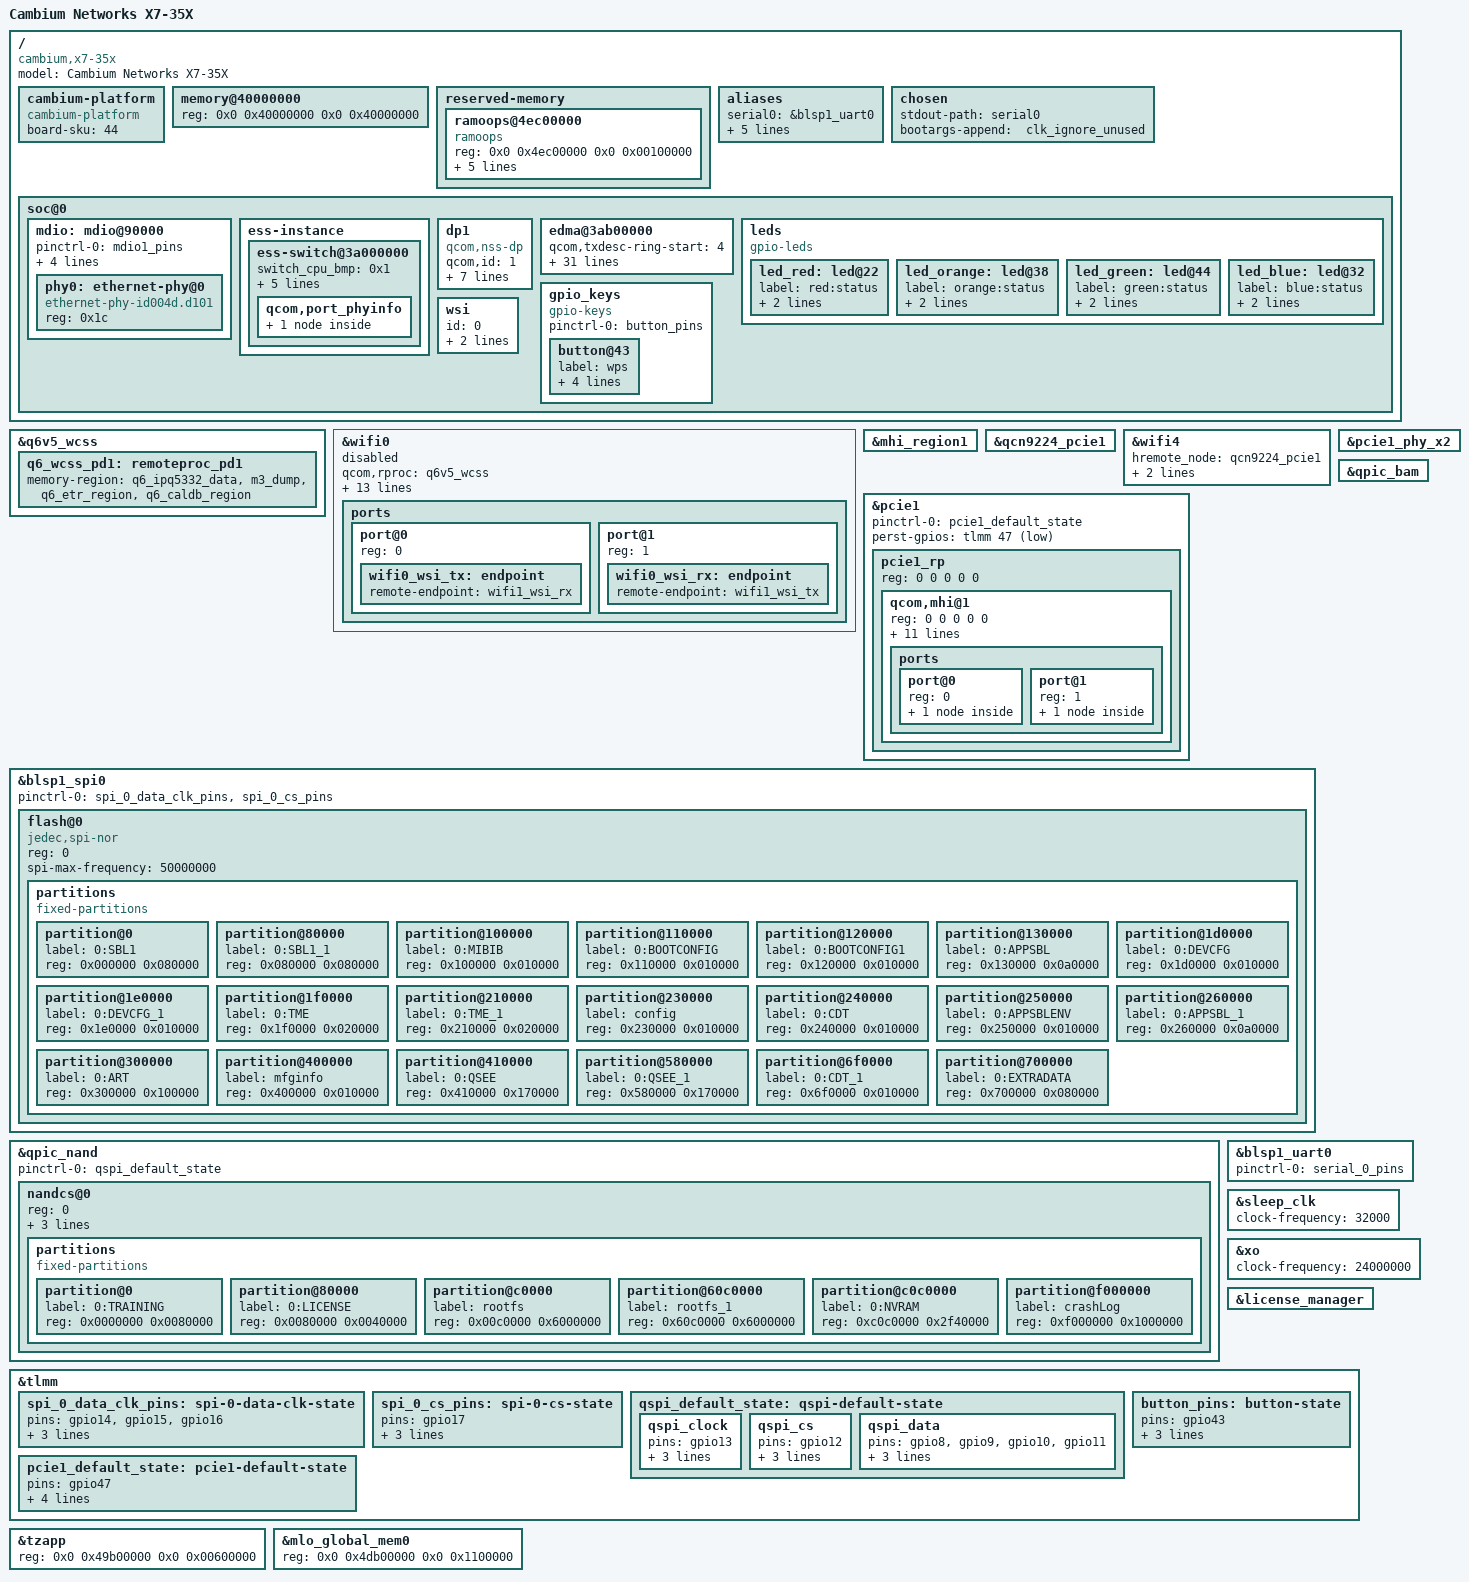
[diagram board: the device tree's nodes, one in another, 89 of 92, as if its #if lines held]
// SPDX-License-Identifier: (GPL-2.0+ OR BSD-3-Clause)
/*
 * Cambium Networks X7-35X device tree source
 *
 * IPQ5332 (2.4 GHz, AHB) + QCN9224 (5 and 6 GHz, PCIe1 x2), tri-band 2x2,
 * one 2.5 GbE port, 1 GiB of DDR, 8 MiB SPI NOR + 256 MiB SPI NAND in two
 * 96 MiB A/B firmware banks. Board codename "acadia", /proc/sku 44,
 * U-Boot hwid=1, machid=0x8060000. Secure boot is off on this unit
 * (qfprom0/authenticate = 0).
 *
 * The OEM tree is "Qualcomm Technologies, Inc. IPQ5332/AP-MI01.6"
 * (qcom,ipq5332-ap-mi01.6), i.e. the same reference design the EAP105 and
 * every other board in this feed descends from, so this file is the EAP105
 * with one port instead of two, the Cambium flash map declared explicitly,
 * and Cambium's LED/button/PHY GPIOs.
 *
 * Every value here comes from one of three places, and nothing else:
 *   - measured on this unit (flash offsets, MAC environment, UBI layout),
 *   - Phil Taylor's validated X7-35X trees (GPIOs, PHY, UNIPHY, LEDs,
 *     reserved memory, board ids),
 *   - the EAP105 twin in this feed (QSDK bindings: nss-dp, ess-switch,
 *     edma, wsi, the QCN9224 MHI node).
 * Anything that could not be sourced from one of those is marked
 * TODO(verify on hardware) rather than guessed.
 */

/dts-v1/;

#define __RPROC_DISABLE_MPD_SUPPORT__

#include <dt-bindings/gpio/gpio.h>
#include <dt-bindings/input/input.h>
#include <dt-bindings/leds/common.h>
#include "ipq5332.dtsi"
#ifdef __IPQ_MEM_PROFILE_512_MB__
#include "ipq5332-512MB-memory.dtsi"
#elif !defined(__IPQ_MEM_PROFILE_256_MB__)
#include "ipq5332-default-memory.dtsi"
#endif

/ {
	model = "Cambium Networks X7-35X";
	compatible = "cambium,x7-35x", "qcom,ipq5332-ap-mi01.6", "qcom,ipq5332";

	/*
	 * The OEM tree has a cambium-platform node whose board-sku is what the
	 * OEM userspace (and Phil's miami-board-data) reads to pick board files
	 * and A/B behaviour. Measured /proc/sku = 44 = 0x2c. Nothing in wlan-ap
	 * reads it today; it is kept so a later Cambium-specific script can use
	 * the same source of truth as the OEM, instead of parsing the model
	 * string.
	 */
	cambium-platform {
		compatible = "cambium-platform";
		board-sku = <44>;
	};


	/*
	 * 2 GiB, MEASURED on this unit -- stock reports MemTotal 1932236 kB and
	 * /proc/device-tree/memory/reg = 0x40000000 size 0x80000000. An earlier
	 * revision of this file said 1 GiB and claimed the Cambium loader was not
	 * known to perform the QSDK memory fixup; the OEM FDT dump disproves both.
	 * That dump carries machid, tz_version, boot_version and a /memreserve/
	 * for the relocated FDT, none of which exist before the loader fixups run.
	 *
	 * Declaring LESS than the installed RAM is merely wasteful; declaring MORE
	 * is fatal. Set to 1 GiB on purpose for now: that is what m0vse's validated
	 * acadia tree declares, and this file is converging on the only known-good
	 * configuration for this SKU. Raise it to 0x80000000 once the board boots.
	 */
	memory@40000000 {
		device_type = "memory";
		reg = <0x0 0x40000000 0x0 0x40000000>;
	};

	/*
	 * ramoops at 0x4ec00000, to get this board to talk without a console.
	 *
	 * An earlier revision of this file deliberately had NO ramoops node,
	 * because the EAP105 twin puts ramoops@49a00000 which lands inside the
	 * tzapp window. That reasoning only ruled out THAT address. 0x4ec00000 is
	 * chosen for one specific property: it is free in our map (once mlo is
	 * corrected below) AND reserved no-map by STOCK, whose OEM DTB has
	 * qcn9224_pcie0@4ec00000 with pcie0 disabled. So stock never writes it,
	 * and after a failed boot self-reverts into stock we can read the buffer
	 * back through stock's /dev/mem. (m0vse's recovery image cannot do this --
	 * it ships no /dev/mem, no pstore and no kexec.)
	 *
	 * mem-type = <1> (uncached) is REQUIRED, not decorative: with a cached
	 * mapping the zone's 12-byte header is still a dirty cache line at reset
	 * while the payload gets written back by capacity eviction, so
	 * persistent_ram_post_init() reads size == 0 and throws the dump away.
	 * That is the WIFI-15350 lesson and it cost a day on the AX820.
	 *
	 * console-size is the whole point: it captures EVERY console line, not
	 * just panics, which is what is needed when the symptom is silence.
	 */
	reserved-memory {
		#address-cells = <2>;
		#size-cells = <2>;
		ranges;

		ramoops@4ec00000 {
			compatible = "ramoops";
			reg = <0x0 0x4ec00000 0x0 0x00100000>;
			record-size  = <0x20000>;
			console-size = <0x80000>;
			pmsg-size    = <0x20000>;
			mem-type     = <1>;
			no-map;
		};
	};

	aliases {
		serial0 = &blsp1_uart0;

		/*
		 * ONE Ethernet port, and it must be ethernet0.
		 *
		 * U-Boot's fdt_fixup_ethernet() walks the aliases ethernet0,
		 * ethernet1, ... and stamps local-mac-address/mac-address onto
		 * each aliased node from the environment variables ethaddr,
		 * eth1addr, ... in that order. Measured on this unit:
		 *   ethaddr = 90:6d:62:b0:64:48 == the label MAC
		 *   eth1addr  does not exist
		 * so the single port must be alias ethernet0 to collect ethaddr.
		 * Aliasing it as ethernet1 (what the XV2-2T0/2T1 and XE3-4 need,
		 * because those carry the label MAC in ethaddr and label+1 in
		 * eth1addr) would leave local-mac-address as the all-zero
		 * placeholder, and nss-dp substitutes a RANDOM MAC for an invalid
		 * one -- a new serial every boot, matching no certificate, so the
		 * controller closes the session right after pushing config.
		 * This is the XV2-2 situation exactly, and the same answer.
		 *
		 * The ipq53xx equivalent of "dp1 aliased as ethernet0" is the
		 * emplus_wap7635 / zyxel_nwa50be single-port pattern already in
		 * this feed: one /soc/dp1 node, aliased ethernet0. The alias
		 * value is a path string, not a phandle, because the dp nodes
		 * carry no label in ipq5332.dtsi -- they are board nodes.
		 */
		ethernet0 = "/soc/dp1";

		led-boot = &led_orange;
		led-failsafe = &led_orange;
		led-running = &led_green;
		led-upgrade = &led_orange;
	};

	chosen {
		stdout-path = "serial0";
		bootargs-append = " clk_ignore_unused";
	};

	soc@0 {
		mdio: mdio@90000 {
			pinctrl-0 = <&mdio1_pins>;	/* gpio27 mdc1, gpio28 mdio1 */
			pinctrl-names = "default";
			/*
			 * QCA8081 reset is GPIO 25 on this board (the EAP105 uses
			 * GPIO 25 for its reset BUTTON -- do not cross-read the two
			 * trees).
			 *
			 * THE POLARITY IS LOAD-BEARING. Do not "correct" it to flag 0
			 * to match the OEM device tree. The OEM 5.4 kernel binds a
			 * driver that hard-codes the pulse and ignores the DT flag, so
			 * its 0 means nothing. On 6.6, qcom,qca-mdio binds
			 * drivers/net/mdio/mdio-ipq4019.c, which takes the line with
			 * devm_gpiod_get_array_optional(..., GPIOD_OUT_LOW) and in
			 * ipq_mdio_reset() asserts, sleeps, then DEASSERTS -- gpiod
			 * honours the flag. With GPIO_ACTIVE_LOW (this value, and
			 * Phil Taylor's validated tree) the pin ends HIGH, releasing
			 * QCA8081 RESET_N. With flag 0 it would end LOW, holding the
			 * PHY in reset: no link, no network, and on a unit with no
			 * serial console, no diagnostics either.
			 *
			 * ipq_mdio_reset() also enables the UNIPHY AHB/SYS clocks and
			 * sets BIT(0) at each eth_ldo before pulsing, which is the
			 * reference-clock enable Phil had to add for mainline -- so
			 * no extra handling is needed here.
			 */
			phy-reset-gpio = <&tlmm 25 GPIO_ACTIVE_LOW>;
			phyaddr_fixup = <0xC90F018>;
			uniphyaddr_fixup = <0xC90F014>;
			mdio_clk_fixup;	/* MDIO clock sequence fix up flag */
			status = "okay";

			/*
			 * QCA8081 (ethernet-phy-id004d.d101) at MDIO address 0x1c.
			 * C22, single port, 1G/2.5G; it presents 2500BASE-X to the
			 * MAC at 2.5 Gbit/s and SGMII below that.
			 *
			 * TODO(verify on hardware): Phil documents that the OEM
			 * qca_mdio_probe enables GCC_UNIPHY0_AHB/SYS and then sets
			 * bit 0 of UNIPHY0 + 0x610 (0x07a00610) -- the QCA8081's
			 * 50 MHz reference clock -- waits 100 ms, and only then
			 * pulses the PHY reset. QSDK does its UNIPHY bring-up in
			 * qca-ssdk from switch_mac_mode rather than from the device
			 * tree, and whether ssdk sets that same bit is NOT
			 * established. If MDIO reads return 0xffff / the PHY never
			 * appears, that bit is the first thing to check, and
			 * base-files/etc/init.d/phy_quirks is the house place to
			 * poke it (see 90-phy_quirks.fragment).
			 */
			phy0: ethernet-phy@0 {
				reg = <0x1c>;
				compatible = "ethernet-phy-id004d.d101";
			};
		};

		ess-instance {
			ess-switch@3a000000 {
				switch_cpu_bmp = <0x1>;		/* cpu port bitmap */
				switch_lan_bmp = <0x2>;		/* lan port bitmap: PPE port 1 */
				switch_wan_bmp = <0x0>;		/* wan port bitmap */
				/*
				 * UNIPHY0 carries the only port. 0xc is
				 * PORT_WRAPPER_SGMII_PLUS (the in-tree comment in
				 * ipq5332-asterfusion-ap7330.dts states 0xc =
				 * SGMII_PLUS and 0xe = 10GBASE_R), which is the 2.5G
				 * mode a QCA8081 needs.
				 *
				 * TODO(verify on hardware): the other single-port
				 * boards in this feed (emplus_wap7635,
				 * zyxel_nwa50be) use 0xf on uniphy0, but both sit
				 * behind a different PHY. If the link never comes up
				 * at 2.5G, or comes up only at 1G, try 0xf before
				 * touching anything else. UNIPHY1 and UNIPHY2 are
				 * unused on this board (0xff = not present).
				 */
				switch_mac_mode = <0xc>;	/* uniphy0 */
				switch_mac_mode1 = <0xff>;	/* uniphy1 unused */
				switch_mac_mode2 = <0xff>;	/* uniphy2 unused */

				qcom,port_phyinfo {
					port@0 {
						port_id = <1>;
						phy_address = <0x1c>;
						mdiobus = <&mdio>;
					};
				};
			};
		};

		/*
		 * The single 2.5G port. PPE port 1 / GMAC at 0x3a500000, which is
		 * the register window the emplus_wap7635 single-port board uses
		 * for its qcom,id = <1>. nss-dp registers it as eth0.
		 * qcom,mactype = <1> is the 2.5G-capable MAC type (the EAP105
		 * uses 1 for its 2.5G port and 0 for its 1G port).
		 *
		 * The EAP105's second node (dp2) is intentionally absent: this AP
		 * has exactly one Ethernet port.
		 */
		dp1 {
			device_type = "network";
			compatible = "qcom,nss-dp";
			qcom,id = <1>;
			reg = <0x3a500000 0x4000>;
			qcom,mactype = <1>;
			local-mac-address = [000000000000];
			mdio-bus = <&mdio>;
			qcom,phy-mdio-addr = <0x1c>;
			qcom,link-poll = <1>;
			phy-mode = "sgmii";
		};

		/*
		 * EDMA host configuration, copied unchanged from the single-port
		 * emplus_wap7635 board in this feed. These are ring/queue
		 * provisioning numbers for the SoC, not board wiring, and are
		 * identical across every ipq53xx board here.
		 */
		edma@3ab00000 {
			qcom,txdesc-ring-start = <4>;
			qcom,txdesc-rings = <12>;
			qcom,mht-txdesc-rings = <8>;
			qcom,txcmpl-ring-start = <4>;
			qcom,txcmpl-rings = <12>;
			qcom,mht-txcmpl-rings = <8>;
			qcom,rxfill-ring-start = <4>;
			qcom,rxfill-rings = <4>;
			qcom,rxdesc-ring-start = <12>;
			qcom,rxdesc-rings = <4>;
			qcom,rx-page-mode = <0>;
			qcom,tx-map-priority-level = <1>;
			qcom,rx-map-priority-level = <1>;
			qcom,ppeds-num = <2>;
			qcom,ppeds-map = <1 1 1 1 32 8>,
					 <2 2 2 2 40 8>;
			qcom,txdesc-map = <8 9 10 11>,
					  <12 13 14 15>,
					  <4 5 6 7>,
					  <16 17 18 19>,
					  <20 21 22 23>;
			qcom,txdesc-fc-grp-map = <1 2 3 4 5>;
			qcom,rxfill-map = <4 5 6 7>;
			qcom,rxdesc-map = <12 13 14 15>;
			qcom,rx-queue-start = <0>;
			qcom,rx-ring-queue-map = <0 8 16 24>,
						 <1 9 17 25>,
						 <2 10 18 26>,
						 <3 11 19 27>,
						 <4 12 20 28>,
						 <5 13 21 29>,
						 <6 14 22 30>,
						 <7 15 23 31>;
			interrupts = <0 163 4>,
				     <0 164 4>,
				     <0 165 4>,
				     <0 166 4>,
				     <0 167 4>,
				     <0 168 4>,
				     <0 169 4>,
				     <0 170 4>,
				     <0 171 4>,
				     <0 172 4>,
				     <0 173 4>,
				     <0 174 4>,
				     <0 139 4>,
				     <0 140 4>,
				     <0 141 4>,
				     <0 142 4>,
				     <0 191 4>,
				     <0 155 4>,
				     <0 156 4>,
				     <0 157 4>,
				     <0 158 4>,
				     <0 160 4>,
				     <0 128 4>,
				     <0 152 4>,
				     <0 161 4>,
				     <0 129 4>,
				     <0 153 4>,
				     <0 175 4>,
				     <0 176 4>,
				     <0 177 4>,
				     <0 178 4>,
				     <0 179 4>,
				     <0 180 4>,
				     <0 181 4>,
				     <0 182 4>;
		};

		/*
		 * LEDs. The OEM cambium-platform led-gpio list is <22 44 38 32> =
		 * red, green, amber, blue, in the order the Jaguar and Cheetah
		 * families use; the OEM lights amber at power-on. Phil checked the
		 * four on an X7-35X: 44 is green, 32 is blue, and 22 and 38 both
		 * light the red/orange element (purple together with blue).
		 *
		 * Labels follow this feed's "<colour>:status" convention so that
		 * board.d/01_leds and the ucentral LED handling can find them.
		 */
		leds {
			compatible = "gpio-leds";

			led_red: led@22 {
				label = "red:status";
				gpios = <&tlmm 22 GPIO_ACTIVE_HIGH>;
				default-state = "off";
			};

			led_orange: led@38 {
				label = "orange:status";
				gpios = <&tlmm 38 GPIO_ACTIVE_HIGH>;
				default-state = "on";
			};

			led_green: led@44 {
				label = "green:status";
				gpios = <&tlmm 44 GPIO_ACTIVE_HIGH>;
				default-state = "off";
			};

			led_blue: led@32 {
				label = "blue:status";
				gpios = <&tlmm 32 GPIO_ACTIVE_HIGH>;
				default-state = "off";
			};
		};

		gpio_keys {
			compatible = "gpio-keys";
			pinctrl-0 = <&button_pins>;
			pinctrl-names = "default";

			/*
			 * GPIO 43, active low, the only button on the unit.
			 * Reported as WPS by the OEM; wlan-ap uses KEY_RESTART for
			 * a factory-reset button. Kept as KEY_WPS_BUTTON, matching
			 * Phil's tree and the OEM silkscreen.
			 * TODO(verify on hardware): whether a long press is meant
			 * to reset -- if so this should be KEY_RESTART so
			 * /etc/rc.button/reset runs.
			 */
			button@43 {
				label = "wps";
				linux,code = <KEY_WPS_BUTTON>;
				gpios = <&tlmm 43 GPIO_ACTIVE_LOW>;
				linux,input-type = <1>;
				debounce-interval = <60>;
			};
		};

		/*
		 * WSI links the IPQ5332 and the QCN9224 so the two chips can form
		 * one MLD. The OEM runs them that way: /sys/class/ieee80211/ on
		 * stock shows mld-phy0 alongside phy1/phy2/phy3.
		 */
		wsi: wsi {
			id = <0>;
			num_chip = <2>;
			status = "okay";
			chip_info = <0 1 1>,
				    <1 1 0>;
		};
	};
};

/* ------------------------------------------------------------------------- */
/* Radios                                                                     */
/* ------------------------------------------------------------------------- */

&q6v5_wcss {
#ifndef __IPQ_MEM_PROFILE_256_MB__
	q6_wcss_pd1: remoteproc_pd1 {
		memory-region = <&q6_ipq5332_data>,
				<&m3_dump>,
				<&q6_etr_region>,
				<&q6_caldb_region>;
	};
#else
	status = "disabled";
	/delete-property/ memory-region;
	q6_wcss_pd1: remoteproc_pd1 {
		status = "disabled";
	};
#endif
};

/* Integrated IPQ5332 radio: 2.4 GHz */
&wifi0 {
	/*
	 * TODO(verify on hardware): the EAP105 wires a per-radio activity LED
	 * here (led-gpio = <&tlmm 36 ...>). The X7-35X's four LEDs are all on
	 * the cambium-platform status list (22/32/38/44) and none is documented
	 * as a radio LED, so no led-gpio is claimed.
	 */
#if defined(__RPROC_DISABLE_MPD_SUPPORT__)
	qcom,rproc = <&q6v5_wcss>;
	dump-region = <&q6_ipq5332_data>,
		<&m3_dump>,
		<&q6_etr_region>,
		<&q6_caldb_region>;
#else
	qcom,rproc = <&q6_wcss_pd1>;
	qcom,rproc_rpd = <&q6v5_wcss>;
	qcom,multipd_arch;
#endif
	qcom,userpd-subsys-name = "q6v5_wcss_userpd1";

#ifndef __IPQ_MEM_PROFILE_256_MB__
	memory-region = <&q6_region>, <&q6_region>, <&q6_ipq5332_data>, <&m3_dump>,
			<&mlo_global_mem0>, <&q6_etr_region>;
	memory-region-names = "q6-region", "q6region-1", "host-ddr-mem", "m3-dump",
			      "mlo-global-mem", "q6-etr-dump";
#endif
	qcom,wsi = <&wsi>;
	qcom,wsi_index = <0>;
	/*
	 * Use the Edgecore EAP105's IPQ5332 board id (0x16) so ath12k loads
	 * EAP105's entry from the ath12k-wifi-edgecore-eap105 board-2.bin - the
	 * closest open-source board data for this IPQ5332 + QCN9274. The QCN
	 * radio's id (0x1019, below) already matches EAP105. Per-unit calibration
	 * still comes from 0:ART; final RF/power validation on X7-35X hardware is
	 * pending.
	 */
	qcom,board_id = <0x16>;
	status = "okay";
	qcom,wsi-controller;
	ports {
		#address-cells = <1>;
		#size-cells = <0>;

		port@0 {
			reg = <0>;

			wifi0_wsi_tx: endpoint {
				remote-endpoint = <&wifi1_wsi_rx>;
			};
		};

		port@1 {
			reg = <1>;

			wifi0_wsi_rx: endpoint {
				remote-endpoint = <&wifi1_wsi_tx>;
			};
		};
	};
};
#ifdef __IPQ_MEM_PROFILE_256_MB__
&wifi0 {
	status = "disabled";
};
#endif

/*
 * QCN9224 (lspci 17cb:1109) on PCIe1, 5 GHz + 6 GHz. Its 50 MiB host window
 * is qcn9224_pcie1 from ipq5332-default-memory.dtsi (0x51f00000, 50 MiB),
 * which is where Phil's tree also puts it (0x51e00000 0x3200000); mhi_region1
 * is the 9 MiB dynamic DMA pool, mlo_global_mem0 the shared MLO region.
 */
&mhi_region1 {
	status = "okay";
};

&qcn9224_pcie1 {
	status = "okay";
};

&wifi4 {
	hremote_node = <&qcn9224_pcie1>;
	/* 0x1019, from the OEM board file bdwlan.b1019-acadia. */
	board_id = <0x1019>;
	node_id = <0x1>;
	status = "okay";
};

&pcie1_phy_x2 {
	status = "okay";
};

&pcie1 {
	pinctrl-0 = <&pcie1_default_state>;
	pinctrl-names = "default";
	/* PERST is GPIO 47, the same line as the EAP105. */
	perst-gpios = <&tlmm 47 GPIO_ACTIVE_LOW>;
	status = "okay";

	pcie1_rp {
		reg = <0 0 0 0 0>;

		qcom,mhi@1 {
			reg = <0 0 0 0 0>;
			/*
			 * TODO(verify on hardware): these boot-args are the
			 * EAP105's rail/GPIO/drive-strength table for its QCN9224
			 * (MX rail on GPIO52, RFA1p2 on GPIO24). They describe the
			 * QCN9224's own power wiring, not the host's, so they are
			 * very likely identical on any AP-MI01.6 derivative, but
			 * they have not been read off this unit. Phil's tree does
			 * not carry an equivalent (upstream ath12k does not use
			 * boot-args), so there is no second source.
			 */
			boot-args = <0x2 0x4 0x34 0x3 0x0 0x0	/* MX rail, GPIO52, drive strength 0x3 */
				     0x4 0x4 0x18 0x3 0x0 0x0	/* RFA1p2 rail, GPIO24, drive strength 0x3 */
				     0x0 0x4 0x0 0x0 0x0 0x0>;	/* end of arguments */
			memory-region = <&qcn9224_pcie1>, <&mhi_region1>, <&mlo_global_mem0>;
			memory-region-names = "host-ddr-mem", "mhi-region", "mlo-global-mem";
			qcom,wsi = <&wsi>;
			qcom,wsi_index = <1>;
			qcom,early_cal_enabled = "supported";
			/*
			 * 0x58800 into 0:ART, confirmed twice: the EAP105 uses the
			 * same offset, and Phil measured the OEM reading 184320
			 * bytes at ART+362496 (0x58800) for this exact unit.
			 */
			qcom,caldata_offset = <0x58800>;
			qcom,board_id = <0x1019>;
			ports {
				#address-cells = <1>;
				#size-cells = <0>;

				port@0 {
					reg = <0>;

					wifi1_wsi_tx: endpoint {
						remote-endpoint = <&wifi0_wsi_rx>;
					};
				};

				port@1 {
					reg = <1>;

					wifi1_wsi_rx: endpoint {
						remote-endpoint = <&wifi0_wsi_tx>;
					};
				};
			};
		};
	};
};

/* ------------------------------------------------------------------------- */
/* Flash                                                                      */
/* ------------------------------------------------------------------------- */

/*
 * Why this board declares partitions and the EAP105 does not.
 *
 * None of the existing ipq53xx trees in this feed carries a partition table:
 * CONFIG_MTD_QCOMSMEM_PARTS is NOT set in config-6.6, so the names those
 * boards use (0:APPSBLENV, 0:ART, rootfs...) come from a full mtdparts= that
 * the QSDK U-Boot injects on the kernel command line.
 *
 * The Cambium U-Boot does not do that. Its bootargs are only
 *   console=ttyMSM0,115200n8 ubi.mtd=rootfs root=/dev/ubiblock0_1 \
 *     rootfstype=squashfs rootwait
 * and it sets mtdids/mtdparts for its own `ubi part` use, not for Linux. With
 * no mtdparts= and no SMEM parser, a tree without a partition table gives
 * Linux a flash with no partitions at all: no 0:ART (no calibration, no
 * radios), no 0:APPSBLENV (no fw_setenv, so no bank flip), no rootfs /
 * rootfs_1 (no sysupgrade). Hence the explicit map below. Same reason the
 * XV2-2T0 series had to declare its NOR map on ipq60xx.
 *
 * Offsets and sizes are the ones measured on this unit, cross-checked against
 * Phil's read of the X7-35X MIBIB (v4). Partitions are NOT marked read-only:
 * wlan-ap needs to write 0:APPSBLENV (fw_setenv) and the inactive firmware
 * bank (sysupgrade). The three that must never be written -- 0:ART, mfginfo
 * and 0:NVRAM -- are left writable only because marking them read-only here
 * would also stop `mtd -qq write` style recovery; they are protected by
 * convention and by cambium-ab's AB_PROTECTED list, not by the tree.
 * TODO(decide): mark 0:ART, mfginfo, 0:NVRAM and the bootloader partitions
 * read-only once the install and recovery flow is settled. Belt and braces.
 */

&blsp1_spi0 {
	pinctrl-0 = <&spi_0_data_clk_pins &spi_0_cs_pins>;
	pinctrl-names = "default";
	status = "okay";

	flash@0 {
		/* MX25U6435F, 8 MiB, 4 KiB erase */
		compatible = "jedec,spi-nor";
		reg = <0>;
		#address-cells = <1>;
		#size-cells = <1>;
		spi-max-frequency = <50000000>;

		partitions {
			compatible = "fixed-partitions";
			#address-cells = <1>;
			#size-cells = <1>;

			partition@0 {
				label = "0:SBL1";
				reg = <0x000000 0x080000>;
			};
			partition@80000 {
				label = "0:SBL1_1";
				reg = <0x080000 0x080000>;
			};
			partition@100000 {
				label = "0:MIBIB";
				reg = <0x100000 0x010000>;
			};
			partition@110000 {
				label = "0:BOOTCONFIG";
				reg = <0x110000 0x010000>;
			};
			partition@120000 {
				label = "0:BOOTCONFIG1";
				reg = <0x120000 0x010000>;
			};
			partition@130000 {
				label = "0:APPSBL";
				reg = <0x130000 0x0a0000>;
			};
			partition@1d0000 {
				label = "0:DEVCFG";
				reg = <0x1d0000 0x010000>;
			};
			partition@1e0000 {
				label = "0:DEVCFG_1";
				reg = <0x1e0000 0x010000>;
			};
			partition@1f0000 {
				label = "0:TME";
				reg = <0x1f0000 0x020000>;
			};
			partition@210000 {
				label = "0:TME_1";
				reg = <0x210000 0x020000>;
			};
			partition@230000 {
				label = "config";
				reg = <0x230000 0x010000>;
			};
			partition@240000 {
				label = "0:CDT";
				reg = <0x240000 0x010000>;
			};
			/*
			 * The U-Boot environment. 30-uboot-envtools finds this by
			 * name in /proc/mtd and, because it is NOR-backed, uses the
			 * partition size as the environment size: /dev/mtdN 0x0
			 * 0x10000 0x1000 0x10.
			 * TODO(verify on hardware): that the Cambium U-Boot's
			 * CONFIG_ENV_SIZE really is 0x10000 and the environment is
			 * single (not redundant). If fw_printenv reports a bad CRC,
			 * that is the mismatch, and the bank flip in platform.sh
			 * will silently not take.
			 */
			partition@250000 {
				label = "0:APPSBLENV";
				reg = <0x250000 0x010000>;
			};
			partition@260000 {
				label = "0:APPSBL_1";
				reg = <0x260000 0x0a0000>;
			};
			partition@300000 {
				label = "0:ART";
				reg = <0x300000 0x100000>;
			};
			partition@400000 {
				label = "mfginfo";
				reg = <0x400000 0x010000>;
			};
			partition@410000 {
				label = "0:QSEE";
				reg = <0x410000 0x170000>;
			};
			partition@580000 {
				label = "0:QSEE_1";
				reg = <0x580000 0x170000>;
			};
			partition@6f0000 {
				label = "0:CDT_1";
				reg = <0x6f0000 0x010000>;
			};
			/*
			 * TODO(verify on hardware): present in Phil's read of the
			 * MIBIB but not in the /proc/mtd listing taken from this
			 * unit, which stops at 0:CDT_1. Harmless if it exists;
			 * delete this node if the MIBIB really ends at 0x700000.
			 */
			partition@700000 {
				label = "0:EXTRADATA";
				reg = <0x700000 0x080000>;
			};
		};
	};
};

&qpic_bam {
	status = "okay";
};

&qpic_nand {
	pinctrl-0 = <&qspi_default_state>;
	pinctrl-names = "default";
	status = "okay";

	/*
	 * MX35UF2GE4AD, 256 MiB, 128 KiB erase, 8-bit BCH over 512-byte steps
	 * (the ECC the Cambium U-Boot writes with). Same strength/step as the
	 * EAP105, so no ECC change is needed.
	 */
	nandcs@0 {
		reg = <0>;
		#address-cells = <1>;
		#size-cells = <1>;

		nand-ecc-strength = <8>;
		nand-ecc-step-size = <512>;
		nand-bus-width = <8>;

		partitions {
			compatible = "fixed-partitions";
			#address-cells = <1>;
			#size-cells = <1>;

			partition@0 {
				label = "0:TRAINING";
				reg = <0x0000000 0x0080000>;
			};
			partition@80000 {
				label = "0:LICENSE";
				reg = <0x0080000 0x0040000>;
			};
			/*
			 * Bank A. Measured: stock boots this one (U-Boot image=0,
			 * cmdline ubi.mtd=rootfs). An install therefore targets
			 * bank B, rootfs_1.
			 *
			 * NOTE for every string match on these names: "rootfs" is
			 * a PREFIX of "rootfs_1". Always test for rootfs_1 first,
			 * or anchor the match (ubi.mtd=rootfs followed by a space).
			 * This is the trap that bit the XV2-2.
			 */
			partition@c0000 {
				label = "rootfs";
				reg = <0x00c0000 0x6000000>;
			};
			/* Bank B. */
			partition@60c0000 {
				label = "rootfs_1";
				reg = <0x60c0000 0x6000000>;
			};
			/*
			 * Cambium's own persistent store, a second UBI device the
			 * OEM mounts at /mnt/flash. Never written by wlan-ap.
			 */
			partition@c0c0000 {
				label = "0:NVRAM";
				reg = <0xc0c0000 0x2f40000>;
			};
			partition@f000000 {
				label = "crashLog";
				reg = <0xf000000 0x1000000>;
			};
		};
	};
};

/* ------------------------------------------------------------------------- */
/* Misc                                                                      */
/* ------------------------------------------------------------------------- */

&blsp1_uart0 {
	pinctrl-0 = <&serial_0_pins>;
	pinctrl-names = "default";
	status = "okay";
};

/*
 * TODO(verify on hardware): the unit has Zigbee and BLE. On the EAP105 the
 * BLE module hangs off blsp1_uart1 (serial_1_pins, left disabled there) and
 * the Sercomm boards use blsp1_uart1 for it too. Nothing has been read off
 * this unit about where Cambium puts either radio, so neither blsp1_uart1 nor
 * blsp1_spi2 nor blsp1_i2c1 is enabled here. They are not needed for
 * Ethernet, Wi-Fi or management.
 */

&sleep_clk {
	clock-frequency = <32000>;
};

&xo {
	clock-frequency = <24000000>;
};

/* 0:LICENSE exists in NAND on this board, so the license manager is wanted. */
&license_manager {
	status = "okay";
};

/*
 * ipq5332.dtsi provides serial_0_pins and mdio1_pins only; every other group
 * below is a board group each ipq53xx board defines for itself. The SPI NOR
 * and QSPI NAND groups are byte-for-byte what the EAP105 declares AND what
 * Phil's ipq5332-miami-flash.dtsi declares for this unit -- two independent
 * sources agreeing, so they are not guesses.
 */
&tlmm {
	spi_0_data_clk_pins: spi-0-data-clk-state {
		pins = "gpio14", "gpio15", "gpio16";
		function = "blsp0_spi";
		drive-strength = <2>;
		bias-pull-down;
	};

	spi_0_cs_pins: spi-0-cs-state {
		pins = "gpio17";
		function = "blsp0_spi";
		drive-strength = <2>;
		bias-pull-up;
	};

	qspi_default_state: qspi-default-state {
		qspi_clock {
			pins = "gpio13";
			function = "qspi_clk";
			drive-strength = <8>;
			bias-pull-down;
		};

		qspi_cs {
			pins = "gpio12";
			function = "qspi_cs";
			drive-strength = <8>;
			bias-pull-up;
		};

		qspi_data {
			pins = "gpio8", "gpio9", "gpio10", "gpio11";
			function = "qspi_data";
			drive-strength = <8>;
			bias-pull-down;
		};
	};

	button_pins: button-state {
		pins = "gpio43";
		function = "gpio";
		drive-strength = <8>;
		bias-pull-up;
	};

	pcie1_default_state: pcie1-default-state {
		pins = "gpio47";
		function = "gpio";
		drive-strength = <8>;
		bias-pull-up;
		output-low;
	};
};

/*
 * TZAPP ADDRESS CORRECTION -- measured against this unit's own OEM device tree.
 *
 * ipq5332.dtsi reserves tzapp at 0x49600000 + 0x600000 in the 1 GiB profile.
 * The OEM DTB dumped from this unit's /sys/firmware/fdt puts it at
 * 0x49B00000 + 0x600000 instead -- 5 MiB higher. Taking the upstream value
 * would leave 0x49C00000..0x4A100000 unreserved, so Linux would treat 5 MiB of
 * TrustZone's application region as free RAM and allocate into it. That is a
 * silent-corruption failure mode, and on this family a TZ-owned region touched
 * by Linux leaves no evidence behind.
 *
 * qseecom consumes this node by phandle (memory-region = <&tzapp>), so the
 * base matters to the driver as well as to the reservation. Match the OEM.
 */
&tzapp {
	reg = <0x0 0x49b00000 0x0 0x00600000>;
};

/*
 * mlo_global_mem_0: 17 MiB, not the 18 MiB ipq5332-default-memory.dtsi
 * declares. Both the OEM DTB and m0vse's validated acadia tree use
 * 0x4db00000 + 0x1100000, and the dtsi's own node names (qcn9224_pcie0@4ec00000,
 * qcn9224_pcie1@51e00000) agree with the OEM while its reg values sit 1 MiB
 * higher -- the oversized mlo is what absorbs the difference. Correcting it
 * matches the hardware and frees 0x4ec00000 for the ramoops buffer above.
 *
 * The two qcn9224 windows are left where the dtsi puts them for now: they are
 * handed to the radio over QMI long after boot, so they cannot affect this, and
 * moving them is a change to make deliberately once the board boots.
 */
&mlo_global_mem0 {
	reg = <0x0 0x4db00000 0x0 0x1100000>;
};
